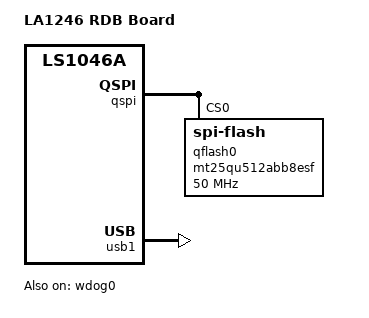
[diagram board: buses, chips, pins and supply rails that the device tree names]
// SPDX-License-Identifier: GPL-2.0+ OR X11
/*
 * Device Tree Include file for NXP Layerscape-1046A family SoC.
 *
 * Copyright 2020-2021 NXP
 *
 */

/dts-v1/;
/include/ "fsl-ls1046a.dtsi"

/ {
	model = "LA1246 RDB Board";

	aliases {
		spi0 = &qspi;
	};

};

&qspi {
	bus-num = <0>;
	status = "okay";

	qflash0: mt25qu512abb8esf@0 {
		#address-cells = <1>;
		#size-cells = <1>;
		compatible = "spi-flash";
		spi-max-frequency = <50000000>;
		reg = <0>;
	};

};

&usb1 {
	status = "okay";
};

&wdog0 {
	status = "okay";
};
